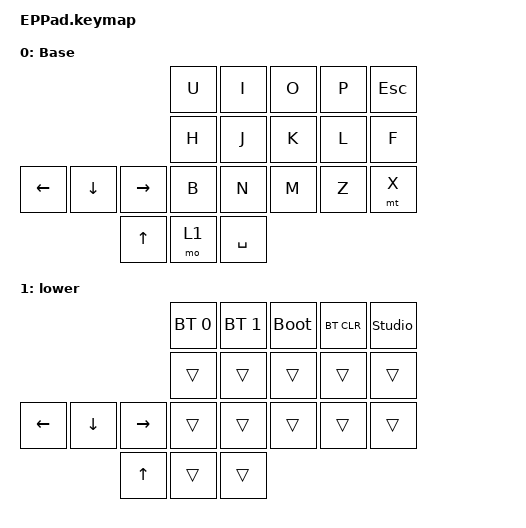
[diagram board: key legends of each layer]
/*
 * Copyright (c) 2023 The ZMK Contributors
 *
 * SPDX-License-Identifier: MIT
 */

#include <behaviors.dtsi>
#include <dt-bindings/zmk/bt.h>
#include <dt-bindings/zmk/keys.h>

/ {
    keymap {
        compatible = "zmk,keymap";

        base {
            display-name = "Base";
            bindings = <
                                &kp U    &kp I    &kp O     &kp P     &kp ESC          
                                &kp H    &kp J    &kp K     &kp L     &kp F         
&kp LEFT  &kp DOWN  &kp RIGHT   &kp B    &kp N    &kp M     &kp Z     &mt X 
                    &kp UP      &mo 1    &kp SPACE  
            >;
            sensor-bindings = <&inc_dec_kp C_VOL_UP C_VOL_DN>;
        };

        lower {
            display-name = "lower";
            bindings = <
                                 &bt BT_SEL 0   &bt BT_SEL 1    &bootloader   &bt BT_CLR  &studio_unlock
                                 &trans         &trans          &trans        &trans      &trans
&kp LEFT   &kp DOWN   &kp RIGHT  &trans         &trans          &trans        &trans      &trans    
                      &kp UP     &trans         &trans    
            >;
            sensor-bindings = <&inc_dec_kp C_VOL_UP C_VOL_DN>;
        };

    };
};
